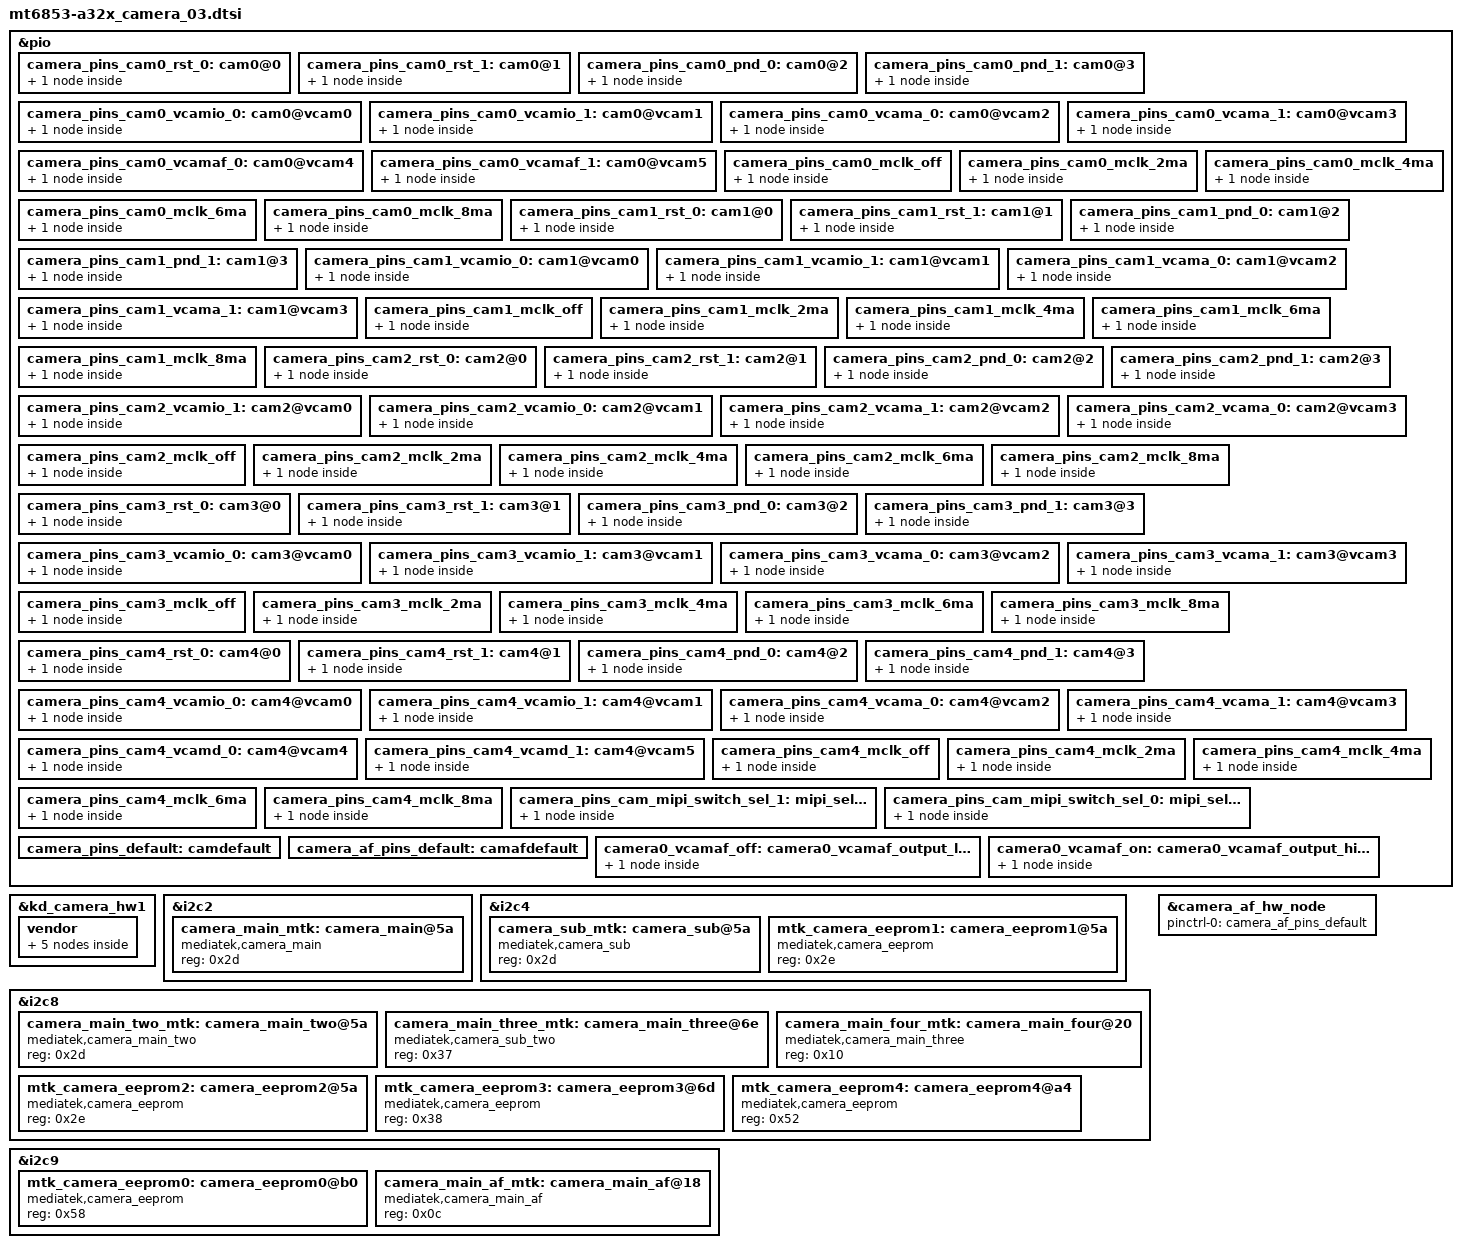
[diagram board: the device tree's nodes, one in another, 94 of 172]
/*
 * Copyright (c) 2019 MediaTek Inc.
 *
 * This program is free software; you can redistribute it and/or modify
 * it under the terms of the GNU General Public License version 2 as
 * published by the Free Software Foundation.
 *
 * This program is distributed in the hope that it will be useful,
 * but WITHOUT ANY WARRANTY; without even the implied warranty of
 * MERCHANTABILITY or FITNESS FOR A PARTICULAR PURPOSE.  See the
 * GNU General Public License for more details.
 */

 /***** A32 5G Bringup Board ********
  *    SW          :   HW   : Sensor
  * camera0(Wide)  : RCAM1  : GM2
  * camera1(Front) : FCAM   : S5K3L6
  * camera2(UW)    : RCAM3  : 4HA -> SR846D
  * camera3(Depth) : RCAM2  : GC02M1B
  * camera4(Macro) : RCAM4  : GC5035
  ***********************************/

/* CAMERA GPIO standardization */
&pio {
	/****************  Camera0  ***************/
	//Reset
	camera_pins_cam0_rst_0: cam0@0 {
		pins_cmd_dat {
			pinmux = <PINMUX_GPIO54__FUNC_GPIO54>;
			slew-rate = <1>;
			output-low;
		};
	};
	camera_pins_cam0_rst_1: cam0@1 {
		pins_cmd_dat {
			pinmux = <PINMUX_GPIO54__FUNC_GPIO54>;
			slew-rate = <1>;
			output-high;
		};
	};
	camera_pins_cam0_pnd_0: cam0@2 {
		pins_cmd_dat {
			pinmux = <PINMUX_GPIO53__FUNC_GPIO53>;
			slew-rate = <1>;
			output-low;
		};
	};
	camera_pins_cam0_pnd_1: cam0@3 {
		pins_cmd_dat {
			pinmux = <PINMUX_GPIO53__FUNC_GPIO53>;
			slew-rate = <1>;
			output-high;
		};
	};

	//VDDIO
	camera_pins_cam0_vcamio_0: cam0@vcam0 {
		pins_cmd_dat {
			pinmux = <PINMUX_GPIO131__FUNC_GPIO131>;
			slew-rate = <1>;
			output-low;
		};
	};
	camera_pins_cam0_vcamio_1: cam0@vcam1 {
		pins_cmd_dat {
			pinmux = <PINMUX_GPIO131__FUNC_GPIO131>;
			slew-rate = <1>;
			output-high;
		};
	};

	//AVDD,DVDD
	camera_pins_cam0_vcama_0: cam0@vcam2 {
		pins_cmd_dat {
			pinmux = <PINMUX_GPIO53__FUNC_GPIO53>;
			slew-rate = <1>;
			output-low;
		};
	};
	camera_pins_cam0_vcama_1: cam0@vcam3 {
		pins_cmd_dat {
			pinmux = <PINMUX_GPIO53__FUNC_GPIO53>;
			slew-rate = <1>;
			output-high;
		};
	};

	//AF
	camera_pins_cam0_vcamaf_0: cam0@vcam4 {
		pins_cmd_dat {
			pinmux = <PINMUX_GPIO132__FUNC_GPIO132>;
			slew-rate = <1>;
			output-low;
		};
	};

	camera_pins_cam0_vcamaf_1: cam0@vcam5 {
		pins_cmd_dat {
			pinmux = <PINMUX_GPIO132__FUNC_GPIO132>;
			slew-rate = <1>;
			output-high;
		};
	};

	//Mclk
	camera_pins_cam0_mclk_off: camera_pins_cam0_mclk_off {
		pins_cmd_dat {
			pinmux = <PINMUX_GPIO49__FUNC_GPIO49>;
			drive-strength = <1>;
		};
	};
	camera_pins_cam0_mclk_2ma: camera_pins_cam0_mclk_2ma {
		pins_cmd_dat {
			pinmux = <PINMUX_GPIO49__FUNC_CMMCLK0>;
			drive-strength = <0>;
		};
	};
	camera_pins_cam0_mclk_4ma: camera_pins_cam0_mclk_4ma {
		pins_cmd_dat {
			pinmux = <PINMUX_GPIO49__FUNC_CMMCLK0>;
			drive-strength = <1>;
		};
	};
	camera_pins_cam0_mclk_6ma: camera_pins_cam0_mclk_6ma {
		pins_cmd_dat {
			pinmux = <PINMUX_GPIO49__FUNC_CMMCLK0>;
			drive-strength = <2>;
		};
	};
	camera_pins_cam0_mclk_8ma: camera_pins_cam0_mclk_8ma {
		pins_cmd_dat {
			pinmux = <PINMUX_GPIO49__FUNC_CMMCLK0>;
			drive-strength = <3>;
		};
	};

	/****************  Camera1  ***************/
	//Reset
	camera_pins_cam1_rst_0: cam1@0 {
		pins_cmd_dat {
			pinmux = <PINMUX_GPIO44__FUNC_GPIO44>;
			slew-rate = <1>;
			output-low;
		};
	};
	camera_pins_cam1_rst_1: cam1@1 {
		pins_cmd_dat {
			pinmux = <PINMUX_GPIO44__FUNC_GPIO44>;
			slew-rate = <1>;
			output-high;
		};
	};
	camera_pins_cam1_pnd_0: cam1@2 {
		pins_cmd_dat {
			pinmux = <PINMUX_GPIO43__FUNC_GPIO43>;
			slew-rate = <1>;
			output-low;
		};
	};
	camera_pins_cam1_pnd_1: cam1@3 {
		pins_cmd_dat {
			pinmux = <PINMUX_GPIO43__FUNC_GPIO43>;
			slew-rate = <1>;
			output-high;
		};
	};

	//VDDIO
	camera_pins_cam1_vcamio_0: cam1@vcam0 {
		pins_cmd_dat {
			pinmux = <PINMUX_GPIO131__FUNC_GPIO131>;
			slew-rate = <1>;
			output-low;
		};
	};
	camera_pins_cam1_vcamio_1: cam1@vcam1 {
		pins_cmd_dat {
			pinmux = <PINMUX_GPIO131__FUNC_GPIO131>;
			slew-rate = <1>;
			output-high;
		};
	};

	//AVDD,DVDD
	camera_pins_cam1_vcama_0: cam1@vcam2 {
		pins_cmd_dat {
			pinmux = <PINMUX_GPIO43__FUNC_GPIO43>;
			slew-rate = <1>;
			output-low;
		};
	};
	camera_pins_cam1_vcama_1: cam1@vcam3 {
		pins_cmd_dat {
			pinmux = <PINMUX_GPIO43__FUNC_GPIO43>;
			slew-rate = <1>;
			output-high;
		};
	};

	//Mclk
	camera_pins_cam1_mclk_off: camera_pins_cam1_mclk_off {
		pins_cmd_dat {
			pinmux = <PINMUX_GPIO52__FUNC_GPIO52>;
			drive-strength = <1>;
		};
	};
	camera_pins_cam1_mclk_2ma: camera_pins_cam1_mclk_2ma {
		pins_cmd_dat {
			pinmux = <PINMUX_GPIO52__FUNC_CMMCLK3>;
			drive-strength = <0>;
		};
	};
	camera_pins_cam1_mclk_4ma: camera_pins_cam1_mclk_4ma {
		pins_cmd_dat {
			pinmux = <PINMUX_GPIO52__FUNC_CMMCLK3>;
			drive-strength = <1>;
		};
	};
	camera_pins_cam1_mclk_6ma: camera_pins_cam1_mclk_6ma {
		pins_cmd_dat {
			pinmux = <PINMUX_GPIO52__FUNC_CMMCLK3>;
			drive-strength = <2>;
		};
	};
	camera_pins_cam1_mclk_8ma: camera_pins_cam1_mclk_8ma {
		pins_cmd_dat {
			pinmux = <PINMUX_GPIO52__FUNC_CMMCLK3>;
			drive-strength = <3>;
		};
	};

	/****************  Camera2  ***************/
	//Reset
	camera_pins_cam2_rst_0: cam2@0 {
		pins_cmd_dat {
			pinmux = <PINMUX_GPIO74__FUNC_GPIO74>;
			slew-rate = <1>;
			output-low;
		};
	};
	camera_pins_cam2_rst_1: cam2@1 {
		pins_cmd_dat {
			pinmux = <PINMUX_GPIO74__FUNC_GPIO74>;
			slew-rate = <1>;
			output-high;
		};
	};
	camera_pins_cam2_pnd_0: cam2@2 {
		pins_cmd_dat {
			pinmux = <PINMUX_GPIO74__FUNC_GPIO74>;
			slew-rate = <1>;
			output-low;
		};
	};
	camera_pins_cam2_pnd_1: cam2@3 {
		pins_cmd_dat {
			pinmux = <PINMUX_GPIO74__FUNC_GPIO74>;
			slew-rate = <1>;
			output-high;
		};
	};

	//VDDIO
	camera_pins_cam2_vcamio_1: cam2@vcam0 {
		pins_cmd_dat {
			pinmux = <PINMUX_GPIO131__FUNC_GPIO131>;
			slew-rate = <1>;
			output-high;
		};
	};
	camera_pins_cam2_vcamio_0: cam2@vcam1 {
		pins_cmd_dat {
			pinmux = <PINMUX_GPIO131__FUNC_GPIO131>;
			slew-rate = <1>;
			output-low;
		};
	};

	//AVDD,DVDD
	camera_pins_cam2_vcama_1: cam2@vcam2 {
		pins_cmd_dat {
			pinmux = <PINMUX_GPIO71__FUNC_GPIO71>;
			slew-rate = <1>;
			output-high;
		};
	};
	camera_pins_cam2_vcama_0: cam2@vcam3 {
		pins_cmd_dat {
			pinmux = <PINMUX_GPIO71__FUNC_GPIO71>;
			slew-rate = <1>;
			output-low;
		};
	};

	//Mclk
	camera_pins_cam2_mclk_off: camera_pins_cam2_mclk_off {
		pins_cmd_dat {
			pinmux = <PINMUX_GPIO51__FUNC_GPIO51>;
			drive-strength = <1>;
		};
	};
	camera_pins_cam2_mclk_2ma: camera_pins_cam2_mclk_2ma {
		pins_cmd_dat {
			pinmux = <PINMUX_GPIO51__FUNC_CMMCLK2>;
			drive-strength = <0>;
		};
	};
	camera_pins_cam2_mclk_4ma: camera_pins_cam2_mclk_4ma {
		pins_cmd_dat {
			pinmux = <PINMUX_GPIO51__FUNC_CMMCLK2>;
			drive-strength = <1>;
		};
	};
	camera_pins_cam2_mclk_6ma: camera_pins_cam2_mclk_6ma {
		pins_cmd_dat {
			pinmux = <PINMUX_GPIO51__FUNC_CMMCLK2>;
			drive-strength = <2>;
		};
	};
	camera_pins_cam2_mclk_8ma: camera_pins_cam2_mclk_8ma {
		pins_cmd_dat {
			pinmux = <PINMUX_GPIO51__FUNC_CMMCLK2>;
			drive-strength = <3>;
		};
	};

	/****************  Camera3  ***************/
	//Reset
	camera_pins_cam3_rst_0: cam3@0 {
		pins_cmd_dat {
			pinmux = <PINMUX_GPIO75__FUNC_GPIO75>;
			slew-rate = <1>;
			output-low;
		};
	};
	camera_pins_cam3_rst_1: cam3@1 {
		pins_cmd_dat {
			pinmux = <PINMUX_GPIO75__FUNC_GPIO75>;
			slew-rate = <1>;
			output-high;
		};
	};
	camera_pins_cam3_pnd_0: cam3@2 {
		pins_cmd_dat {
			pinmux = <PINMUX_GPIO75__FUNC_GPIO75>;
			slew-rate = <1>;
			output-low;
		};
	};
	camera_pins_cam3_pnd_1: cam3@3 {
		pins_cmd_dat {
			pinmux = <PINMUX_GPIO75__FUNC_GPIO75>;
			slew-rate = <1>;
			output-high;
		};
	};

	//VDDIO
	camera_pins_cam3_vcamio_0: cam3@vcam0 {
		pins_cmd_dat {
			pinmux = <PINMUX_GPIO131__FUNC_GPIO131>;
			slew-rate = <1>;
			output-low;
		};
	};
	camera_pins_cam3_vcamio_1: cam3@vcam1 {
		pins_cmd_dat {
			pinmux = <PINMUX_GPIO131__FUNC_GPIO131>;
			slew-rate = <1>;
			output-high;
		};
	};

	//AVDD,DVDD
	camera_pins_cam3_vcama_0: cam3@vcam2 {
		pins_cmd_dat {
			pinmux = <PINMUX_GPIO70__FUNC_GPIO70>;
			slew-rate = <1>;
			output-low;
		};
	};
	camera_pins_cam3_vcama_1: cam3@vcam3 {
		pins_cmd_dat {
			pinmux = <PINMUX_GPIO70__FUNC_GPIO70>;
			slew-rate = <1>;
			output-high;
		};
	};

	//Mclk
	camera_pins_cam3_mclk_off: camera_pins_cam3_mclk_off {
		pins_cmd_dat {
			pinmux = <PINMUX_GPIO50__FUNC_GPIO50>;
			drive-strength = <1>;
		};
	};
	camera_pins_cam3_mclk_2ma: camera_pins_cam3_mclk_2ma {
		pins_cmd_dat {
			pinmux = <PINMUX_GPIO50__FUNC_CMMCLK1>;
			drive-strength = <0>;
		};
	};
	camera_pins_cam3_mclk_4ma: camera_pins_cam3_mclk_4ma {
		pins_cmd_dat {
			pinmux = <PINMUX_GPIO50__FUNC_CMMCLK1>;
			drive-strength = <1>;
		};
	};
	camera_pins_cam3_mclk_6ma: camera_pins_cam3_mclk_6ma {
		pins_cmd_dat {
			pinmux = <PINMUX_GPIO50__FUNC_CMMCLK1>;
			drive-strength = <2>;
		};
	};
	camera_pins_cam3_mclk_8ma: camera_pins_cam3_mclk_8ma {
		pins_cmd_dat {
			pinmux = <PINMUX_GPIO50__FUNC_CMMCLK1>;
			drive-strength = <3>;
		};
	};

	/****************  Camera4  ***************/
	//Reset
	camera_pins_cam4_rst_0: cam4@0 {
		pins_cmd_dat {
			pinmux = <PINMUX_GPIO60__FUNC_GPIO60>;
			slew-rate = <1>;
			output-low;
		};
	};
	camera_pins_cam4_rst_1: cam4@1 {
		pins_cmd_dat {
			pinmux = <PINMUX_GPIO60__FUNC_GPIO60>;
			slew-rate = <1>;
			output-high;
		};
	};
	camera_pins_cam4_pnd_0: cam4@2 {
		pins_cmd_dat {
			pinmux = <PINMUX_GPIO59__FUNC_GPIO59>;
			slew-rate = <1>;
			output-low;
		};
	};
	camera_pins_cam4_pnd_1: cam4@3 {
		pins_cmd_dat {
			pinmux = <PINMUX_GPIO59__FUNC_GPIO59>;
			slew-rate = <1>;
			output-high;
		};
	};

	//VDDIO/AVDD/DVDD
	camera_pins_cam4_vcamio_0: cam4@vcam0 {
		pins_cmd_dat {
			pinmux = <PINMUX_GPIO131__FUNC_GPIO131>;
			slew-rate = <1>;
			output-low;
		};
	};
	camera_pins_cam4_vcamio_1: cam4@vcam1 {
		pins_cmd_dat {
			pinmux = <PINMUX_GPIO131__FUNC_GPIO131>;
			slew-rate = <1>;
			output-high;
		};
	};
	camera_pins_cam4_vcama_0: cam4@vcam2 {
		pins_cmd_dat {
			pinmux = <PINMUX_GPIO70__FUNC_GPIO70>;
			slew-rate = <1>;
			output-low;
		};
	};
	camera_pins_cam4_vcama_1: cam4@vcam3 {
		pins_cmd_dat {
			pinmux = <PINMUX_GPIO70__FUNC_GPIO70>;
			slew-rate = <1>;
			output-high;
		};
	};
	camera_pins_cam4_vcamd_0: cam4@vcam4 {
		pins_cmd_dat {
			pinmux = <PINMUX_GPIO59__FUNC_GPIO59>;
			slew-rate = <1>;
			output-low;
		};
	};
	camera_pins_cam4_vcamd_1: cam4@vcam5 {
		pins_cmd_dat {
			pinmux = <PINMUX_GPIO59__FUNC_GPIO59>;
			slew-rate = <1>;
			output-high;
		};
	};

	//Mclk
	camera_pins_cam4_mclk_off: camera_pins_cam4_mclk_off {
		pins_cmd_dat {
			pinmux = <PINMUX_GPIO51__FUNC_GPIO51>;
			drive-strength = <1>;
		};
	};
	camera_pins_cam4_mclk_2ma: camera_pins_cam4_mclk_2ma {
		pins_cmd_dat {
			pinmux = <PINMUX_GPIO51__FUNC_CMMCLK2>;
			drive-strength = <0>;
		};
	};
	camera_pins_cam4_mclk_4ma: camera_pins_cam4_mclk_4ma {
		pins_cmd_dat {
			pinmux = <PINMUX_GPIO51__FUNC_CMMCLK2>;
			drive-strength = <1>;
		};
	};
	camera_pins_cam4_mclk_6ma: camera_pins_cam4_mclk_6ma {
		pins_cmd_dat {
			pinmux = <PINMUX_GPIO51__FUNC_CMMCLK2>;
			drive-strength = <2>;
		};
	};
	camera_pins_cam4_mclk_8ma: camera_pins_cam4_mclk_8ma {
		pins_cmd_dat {
			pinmux = <PINMUX_GPIO51__FUNC_CMMCLK2>;
			drive-strength = <3>;
		};
	};

	//MIPI switch for camera1 and camera2
	camera_pins_cam_mipi_switch_sel_1: mipi_sel@1 {
		pins_cmd_dat {
			pinmux = <PINMUX_GPIO37__FUNC_GPIO37>;
			slew-rate = <1>;
			output-high;
		};
	};
	camera_pins_cam_mipi_switch_sel_0: mipi_sel@0 {
		pins_cmd_dat {
			pinmux = <PINMUX_GPIO37__FUNC_GPIO37>;
			slew-rate = <1>;
			output-low;
		};
	};

	camera_pins_default: camdefault {
	};
};
&kd_camera_hw1 {
	pinctrl-names = "default",
			"cam0_rst0", "cam0_rst1",
			"cam0_pnd0", "cam0_pnd1",
			"cam1_rst0", "cam1_rst1",
			"cam1_pnd0", "cam1_pnd1",
			"cam2_rst0", "cam2_rst1",
			"cam2_pnd0", "cam2_pnd1",
			"cam3_rst0", "cam3_rst1",
			"cam3_pnd0", "cam3_pnd1",
			"cam4_rst0", "cam4_rst1",
			"cam4_pnd0", "cam4_pnd1",
			"cam0_ldo_vcamio_0", "cam0_ldo_vcamio_1",
			"cam0_ldo_vcama_0", "cam0_ldo_vcama_1",
			"cam0_ldo_vcamaf_0", "cam0_ldo_vcamaf_1",
			"cam1_ldo_vcamio_0", "cam1_ldo_vcamio_1",
			"cam1_ldo_vcama_0", "cam1_ldo_vcama_1",
			"cam2_ldo_vcamio_0", "cam2_ldo_vcamio_1",
			"cam2_ldo_vcama_0", "cam2_ldo_vcama_1",
			"cam3_ldo_vcamio_0", "cam3_ldo_vcamio_1",
			"cam3_ldo_vcama_0", "cam3_ldo_vcama_1",
			"cam4_ldo_vcamio_0", "cam4_ldo_vcamio_1",
			"cam4_ldo_vcama_0", "cam4_ldo_vcama_1",
			"cam4_ldo_vcamd_0", "cam4_ldo_vcamd_1",
			"cam0_mclk_off",
			"cam0_mclk_2mA", "cam0_mclk_4mA",
			"cam0_mclk_6mA", "cam0_mclk_8mA",
			"cam1_mclk_off",
			"cam1_mclk_2mA", "cam1_mclk_4mA",
			"cam1_mclk_6mA", "cam1_mclk_8mA",
			"cam2_mclk_off",
			"cam2_mclk_2mA", "cam2_mclk_4mA",
			"cam2_mclk_6mA", "cam2_mclk_8mA",
			"cam3_mclk_off",
			"cam3_mclk_2mA", "cam3_mclk_4mA",
			"cam3_mclk_6mA", "cam3_mclk_8mA",
			"cam4_mclk_off",
			"cam4_mclk_2mA", "cam4_mclk_4mA",
			"cam4_mclk_6mA", "cam4_mclk_8mA",
			"cam_mipi_switch_sel_1", "cam_mipi_switch_sel_0";
	pinctrl-0 = <&camera_pins_default>;
	pinctrl-1 = <&camera_pins_cam0_rst_0>;
	pinctrl-2 = <&camera_pins_cam0_rst_1>;
	pinctrl-3 = <&camera_pins_cam0_pnd_0>;
	pinctrl-4 = <&camera_pins_cam0_pnd_1>;
	pinctrl-5 = <&camera_pins_cam1_rst_0>;
	pinctrl-6 = <&camera_pins_cam1_rst_1>;
	pinctrl-7 = <&camera_pins_cam1_pnd_0>;
	pinctrl-8 = <&camera_pins_cam1_pnd_1>;
	pinctrl-9 = <&camera_pins_cam2_rst_0>;
	pinctrl-10 = <&camera_pins_cam2_rst_1>;
	pinctrl-11 = <&camera_pins_cam2_pnd_0>;
	pinctrl-12 = <&camera_pins_cam2_pnd_1>;
	pinctrl-13 = <&camera_pins_cam3_rst_0>;
	pinctrl-14 = <&camera_pins_cam3_rst_1>;
	pinctrl-15 = <&camera_pins_cam3_pnd_0>;
	pinctrl-16 = <&camera_pins_cam3_pnd_1>;
	pinctrl-17 = <&camera_pins_cam4_rst_0>;
	pinctrl-18 = <&camera_pins_cam4_rst_1>;
	pinctrl-19 = <&camera_pins_cam4_pnd_0>;
	pinctrl-20 = <&camera_pins_cam4_pnd_1>;
	pinctrl-21 = <&camera_pins_cam0_vcamio_0>;
	pinctrl-22 = <&camera_pins_cam0_vcamio_1>;
	pinctrl-23 = <&camera_pins_cam0_vcama_0>;
	pinctrl-24 = <&camera_pins_cam0_vcama_1>;
	pinctrl-25 = <&camera_pins_cam0_vcamaf_0>;
	pinctrl-26 = <&camera_pins_cam0_vcamaf_1>;
	pinctrl-27 = <&camera_pins_cam1_vcamio_0>;
	pinctrl-28 = <&camera_pins_cam1_vcamio_1>;
	pinctrl-29 = <&camera_pins_cam1_vcama_0>;
	pinctrl-30 = <&camera_pins_cam1_vcama_1>;
	pinctrl-31 = <&camera_pins_cam2_vcamio_0>;
	pinctrl-32 = <&camera_pins_cam2_vcamio_1>;
	pinctrl-33 = <&camera_pins_cam2_vcama_0>;
	pinctrl-34 = <&camera_pins_cam2_vcama_1>;
	pinctrl-35 = <&camera_pins_cam3_vcamio_0>;
	pinctrl-36 = <&camera_pins_cam3_vcamio_1>;
	pinctrl-37 = <&camera_pins_cam3_vcama_0>;
	pinctrl-38 = <&camera_pins_cam3_vcama_1>;
	pinctrl-39 = <&camera_pins_cam4_vcamio_0>;
	pinctrl-40 = <&camera_pins_cam4_vcamio_1>;
	pinctrl-41 = <&camera_pins_cam4_vcama_0>;
	pinctrl-42 = <&camera_pins_cam4_vcama_1>;
	pinctrl-43 = <&camera_pins_cam4_vcamd_0>;
	pinctrl-44 = <&camera_pins_cam4_vcamd_1>;
	pinctrl-45 = <&camera_pins_cam0_mclk_off>;
	pinctrl-46 = <&camera_pins_cam0_mclk_2ma>;
	pinctrl-47 = <&camera_pins_cam0_mclk_4ma>;
	pinctrl-48 = <&camera_pins_cam0_mclk_6ma>;
	pinctrl-49 = <&camera_pins_cam0_mclk_8ma>;
	pinctrl-50 = <&camera_pins_cam1_mclk_off>;
	pinctrl-51 = <&camera_pins_cam1_mclk_2ma>;
	pinctrl-52 = <&camera_pins_cam1_mclk_4ma>;
	pinctrl-53 = <&camera_pins_cam1_mclk_6ma>;
	pinctrl-54 = <&camera_pins_cam1_mclk_8ma>;
	pinctrl-55 = <&camera_pins_cam2_mclk_off>;
	pinctrl-56 = <&camera_pins_cam2_mclk_2ma>;
	pinctrl-57 = <&camera_pins_cam2_mclk_4ma>;
	pinctrl-58 = <&camera_pins_cam2_mclk_6ma>;
	pinctrl-59 = <&camera_pins_cam2_mclk_8ma>;
	pinctrl-60 = <&camera_pins_cam3_mclk_off>;
	pinctrl-61 = <&camera_pins_cam3_mclk_2ma>;
	pinctrl-62 = <&camera_pins_cam3_mclk_4ma>;
	pinctrl-63 = <&camera_pins_cam3_mclk_6ma>;
	pinctrl-64 = <&camera_pins_cam3_mclk_8ma>;
	pinctrl-65 = <&camera_pins_cam4_mclk_off>;
	pinctrl-66 = <&camera_pins_cam4_mclk_2ma>;
	pinctrl-67 = <&camera_pins_cam4_mclk_4ma>;
	pinctrl-68 = <&camera_pins_cam4_mclk_6ma>;
	pinctrl-69 = <&camera_pins_cam4_mclk_8ma>;
	pinctrl-70 = <&camera_pins_cam_mipi_switch_sel_1>;
	pinctrl-71 = <&camera_pins_cam_mipi_switch_sel_0>;

	status = "okay";
	vendor {
		rear_sensor_id = <120>;    /* SENSOR_NAME_GM2 */
		front_sensor_id = <121>;    /* SENSOR_NAME_S5K3L6 */
		rear2_sensor_id = <210>;    /* SENSOR_NAME_4HA */
		rear3_sensor_id = <211>;    /* SENSOR_NAME_GC02M1B*/
		rear4_sensor_id = <210>;    /* SENSOR_NAME_GC5035 or SENSOR_NAME_GC02M1*/

		/* Use set calibration for processing raw calibaration data in Samsung side instead of outsourcing */
		use_dualcam_set_cal;
		use_module_check;
		check_final_cam_module;
		//skip_cal_loading;
		max_supported_camera = <6>;
		supported_cameraId = <0 1 23 50 52 54>;
		/* REAR, FRONT, DUAL_REAR_PORTRAIT_WIDE(Bokeh), REAR_2, REAR_3, REAR_4(Macro) */

		max_camera_num = <5>;
		camera_info0 {             /* 0 : rear - GM2 */
			isp = <0>;             /* 0 : INT , 1 : EXT , 2 : SOC */
			cal_memory = <2>;      /* 0 : N , 1 : FROM , 2 : EEPROM , 3 : OTP  */
			read_version = <0>;    /* 0 : SYSFS , 1 : CAMON */
			core_voltage = <0>;    /* 0 : N , 1 : Y  */
			upgrade = <0>;         /* 0 : N , 1 : SYSFS , 2 : CAMON */
			companion = <0>;       /* 0 : N , 1 : Y  */
			ois = <0>;             /* 0 : N , 1 : Y  */
			valid = <1>;           /* 0 : INVALID, 1 : VALID */
			dual_open = <0>;       /* 0 : SINGLE_OPEN , 1 : DUAL_OPEN */
			position = <0>;        /* 0 : Rear, 1:Front, 2:Rear2, 3:Front2, 4:Rear3, 6:Rear4 */
			//includes_sub = <4>;    /* include this for common eeprom. <_position_> - position of the sub camera */
			afcal_type=<20>;        /* output format - 1: Near, Middle..., Far , 20: Near, Far, Middle... */
		};
		camera_info1 {             /* 1 : front1 - 3L6 */
			isp = <0>;             /* 0 : INT , 1 : EXT , 2 : SOC */
			cal_memory = <3>;      /* 0 : N , 1 : FROM , 2 : EEPROM , 3 : OTP  */
			read_version = <0>;    /* 0 : SYSFS , 1 : CAMON */
			core_voltage = <0>;    /* 0 : N , 1 : Y  */
			upgrade = <0>;         /* 0 : N , 1 : SYSFS , 2 : CAMON */
			companion = <0>;       /* 0 : N , 1 : Y  */
			ois = <0>;             /* 0 : N , 1 : Y  */
			valid = <1>;           /* 0 : INVALID, 1 : VALID */
			dual_open = <0>;       /* 0 : SINGLE_OPEN , 1 : DUAL_OPEN */
			position = <1>;        /* 0 : Rear, 1:Front, 2:Rear2, 3:Front2, 4:Rear3, 6:Rear4 */
		};
		camera_info2 {             /* 2 : rear2 - 4HA */
			isp = <0>;             /* 0 : INT , 1 : EXT , 2 : SOC */
			cal_memory = <3>;      /* 0 : N , 1 : FROM , 2 : EEPROM , 3 : OTP  */
			read_version = <0>;    /* 0 : SYSFS , 1 : CAMON */
			core_voltage = <0>;    /* 0 : N , 1 : Y  */
			upgrade = <0>;         /* 0 : N , 1 : SYSFS , 2 : CAMON */
			companion = <0>;       /* 0 : N , 1 : Y  */
			ois = <0>;             /* 0 : N , 1 : Y  */
			valid = <1>;           /* 0 : INVALID, 1 : VALID */
			dual_open = <0>;       /* 0 : SINGLE_OPEN , 1 : DUAL_OPEN */
			position = <2>;        /* 0 : Rear, 1:Front, 2:Rear2, 3:Front2, 4:Rear3, 6:Rear4 */
		};
		camera_info3 {             /* 2 : rear3 - GC02M1B */
			isp = <0>;             /* 0 : INT , 1 : EXT , 2 : SOC */
			cal_memory = <2>;      /* 0 : N , 1 : FROM , 2 : EEPROM , 3 : OTP  */
			read_version = <0>;    /* 0 : SYSFS , 1 : CAMON */
			core_voltage = <0>;    /* 0 : N , 1 : Y  */
			upgrade = <0>;         /* 0 : N , 1 : SYSFS , 2 : CAMON */
			companion = <0>;       /* 0 : N , 1 : Y  */
			ois = <0>;             /* 0 : N , 1 : Y  */
			valid = <1>;           /* 0 : INVALID, 1 : VALID */
			dual_open = <1>;       /* 0 : SINGLE_OPEN , 1 : DUAL_OPEN */
			position = <4>;        /* 0 : Rear, 1:Front, 2:Rear2, 3:Front2, 4:Rear3, 6:Rear4 */
		};
		camera_info4 {             /* 2 : rear4 - GC5035 or GC02M1*/
			isp = <0>;             /* 0 : INT , 1 : EXT , 2 : SOC */
			cal_memory = <3>;      /* 0 : N , 1 : FROM , 2 : EEPROM , 3 : OTP  */
			read_version = <0>;    /* 0 : SYSFS , 1 : CAMON */
			core_voltage = <0>;    /* 0 : N , 1 : Y  */
			upgrade = <0>;         /* 0 : N , 1 : SYSFS , 2 : CAMON */
			companion = <0>;       /* 0 : N , 1 : Y  */
			ois = <0>;             /* 0 : N , 1 : Y  */
			valid = <1>;           /* 0 : INVALID, 1 : VALID */
			dual_open = <0>;       /* 0 : SINGLE_OPEN , 1 : DUAL_OPEN */
			position = <6>;        /* 0 : Rear, 1:Front, 2:Rear2, 3:Front2, 4:Rear3, 6:Rear4 */
		};
	};
};
/* CAMERA GPIO end */

/************************************
 *			Camera I2C
 ************************************/
&i2c2 {
	#address-cells = <1>;
	#size-cells = <0>;
	clock-frequency = <400000>;
	mediatek,use-open-drain;

	camera_main_mtk:camera_main@5a {
		compatible = "mediatek,camera_main";
		reg = <0x2d>;
		status = "okay";
	};
};

&i2c4 {
	#address-cells = <1>;
	#size-cells = <0>;
	clock-frequency = <400000>;
	mediatek,use-open-drain;

	camera_sub_mtk:camera_sub@5a {
		compatible = "mediatek,camera_sub";
		reg = <0x2d>;
		status = "okay";
	};
	mtk_camera_eeprom1:camera_eeprom1@5a {
		compatible = "mediatek,camera_eeprom";
		reg = <0x2e>;
		status = "okay";
	};
};

&i2c8 {
	#address-cells = <1>;
	#size-cells = <0>;
	clock-frequency = <400000>;
	mediatek,use-open-drain;

	camera_main_two_mtk:camera_main_two@5a {
		compatible = "mediatek,camera_main_two";
		reg = <0x2d>;
		status = "okay";
	};
	camera_main_three_mtk:camera_main_three@6e {
		compatible = "mediatek,camera_sub_two";
		reg = <0x37>;
		status = "okay";
	};
	camera_main_four_mtk:camera_main_four@20 {
		compatible = "mediatek,camera_main_three";
		reg = <0x10>;
		status = "okay";
	};
	mtk_camera_eeprom2:camera_eeprom2@5a {
		compatible = "mediatek,camera_eeprom";
		reg = <0x2e>;
		status = "okay";
	};
	mtk_camera_eeprom3:camera_eeprom3@6d {
		compatible = "mediatek,camera_eeprom";
		reg = <0x38>;
		status = "okay";
	};
	mtk_camera_eeprom4:camera_eeprom4@a4 {
		compatible = "mediatek,camera_eeprom";
		reg = <0x52>;
		status = "okay";
	};
};

&i2c9 {
	#address-cells = <1>;
	#size-cells = <0>;
	clock-frequency = <400000>;
	mediatek,use-open-drain;

	mtk_camera_eeprom0:camera_eeprom0@b0 {
		compatible = "mediatek,camera_eeprom";
		reg = <0x58>;
		status = "okay";
	};
	camera_main_af_mtk:camera_main_af@18 {
		compatible = "mediatek,camera_main_af";
		reg = <0x0c>;
		status = "okay";
	};
};
/* CAMERA I2C end */

/* CAMERA AF */
&pio {
	camera_af_pins_default: camafdefault {
	};
	camera0_vcamaf_off: camera0_vcamaf_output_low@gpio132 {
		pins_cmd_dat {
			pinmux = <PINMUX_GPIO132__FUNC_GPIO132>;
			slew-rate = <1>;
			output-low;
		};
	};
	camera0_vcamaf_on: camera0_vcamaf_output_high@gpio132 {
		pins_cmd_dat {
			pinmux = <PINMUX_GPIO132__FUNC_GPIO132>;
			slew-rate = <1>;
			output-high;
		};
	};
};

&camera_af_hw_node {
	pinctrl-names = "default";
	//		"cam0_ldo_vcamaf_0", "cam0_ldo_vcamaf_1";
	pinctrl-0 = <&camera_af_pins_default>;
	//pinctrl-1 = <&camera0_vcamaf_off>;
	//pinctrl-2 = <&camera0_vcamaf_on>;
	status = "okay";
};
/* CAMERA AF end */
